# STM32MP23_CM33 register map
File version: 1.2
CPU: CM33 r0p1, little endian, MPU, FPU, vendor SysTick, 8 interrupt priority bits
Registers are 32-bit, read-write, reset 0x0 unless marked. A register's access mark holds for its fields unless they carry their own. Offsets are from the block's base; [hi:lo] are bit positions; {n}, {i} and the like mark numbered series; 'fields as' and 'values as' point back to an identical list.

## EXTI1 (part 2 of 2) — EXTI1 address block description
Base 0x44220000
Same registers: EXTI1_S 0x54220000
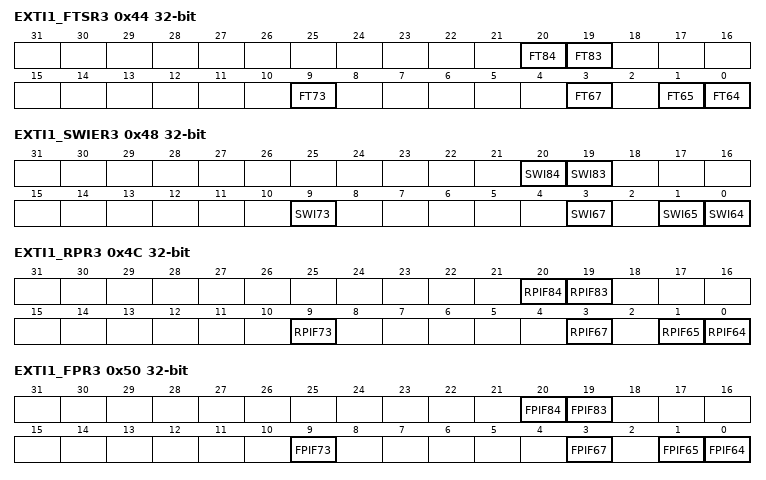
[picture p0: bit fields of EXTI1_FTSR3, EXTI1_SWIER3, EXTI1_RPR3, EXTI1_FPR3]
0x44 EXTI1_FTSR3 — EXTI1 falling trigger selection register
  [20] FT84 — Falling trigger event configuration bit of configurable event input x When SECx is disabled in EXTI1_SECCFGR3, FTx can be accessed with non-secure and secure access. When SECx is enabled in EXTI1_SECCFGR3, FTx can only be accessed with secure access. Non-secure write to FTx is discarded. Non-secure read returns 0. When PRIVx is disabled in EXTI1_PRIVCFGR3, FTx can be accessed with unprivileged and privileged access. When PRIVx is enabled in EXTI1_PRIVCFGR3, FTx can only be accessed with privileged access. Unprivileged write to FTx is discarded. Unprivileged read returns 0. When CID filtering is disabled in EXTI1_ExCIDCFGR, FTx can be accessed by any processor CID. When CID filtering is enabled in EXTI1_ExCIDCFGR, FTx can only be accessed by the allowed processor CID. Dis allowed CID write to FTx is discarded and read returns 0. Note: The configurable event input is edge triggered. No glitch must be generated on this input. If a falling edge on the configurable event input occurs while writing to the register, the associated pending bit is not set. Note: Rising and falling edge triggers can be set for the same configurable event input. In this case, both edges generate a trigger.
    0=Falling trigger disabled (for event and interrupt) for input line; 1=Falling trigger enabled (for event and interrupt) for input line
  [19] FT83 — Falling trigger event configuration bit of configurable event input x When SECx is disabled in EXTI1_SECCFGR3, FTx can be accessed with non-secure and secure access. When SECx is enabled in EXTI1_SECCFGR3, FTx can only be accessed with secure access. Non-secure write to FTx is discarded. Non-secure read returns 0. When PRIVx is disabled in EXTI1_PRIVCFGR3, FTx can be accessed with unprivileged and privileged access. When PRIVx is enabled in EXTI1_PRIVCFGR3, FTx can only be accessed with privileged access. Unprivileged write to FTx is discarded. Unprivileged read returns 0. When CID filtering is disabled in EXTI1_ExCIDCFGR, FTx can be accessed by any processor CID. When CID filtering is enabled in EXTI1_ExCIDCFGR, FTx can only be accessed by the allowed processor CID. Dis allowed CID write to FTx is discarded and read returns 0. Note: The configurable event input is edge triggered. No glitch must be generated on this input. If a falling edge on the configurable event input occurs while writing to the register, the associated pending bit is not set. Note: Rising and falling edge triggers can be set for the same configurable event input. In this case, both edges generate a trigger.
    values as FT84
  [9] FT73 — Falling trigger event configuration bit of configurable event input 73
  [3] FT67 — Falling trigger event configuration bit of configurable event input 67
  [1] FT65 — Falling trigger event configuration bit of configurable event input x
  [0] FT64 — Falling trigger event configuration bit of configurable event input x
0x48 EXTI1_SWIER3 — EXTI1 software interrupt event register
  [20] SWI84 — Software interrupt on event x When SECx is disabled in EXTI1_SECCFGR3, SWIx can be accessed with non-secure and secure access. When SECx is enabled in EXTI1_SECCFGR3, SWIx can only be accessed with secure access. Non-secure write to SWIx is discarded. Non-secure read returns 0. When PRIVx is disabled in EXTI1_PRIVCFGR3, SWIx can be accessed with unprivileged and privileged access. When PRIVx is enabled in EXTI1_PRIVCFGR3, SWIx can only be accessed with privileged access. Unprivileged write to SWIx is discarded. Unprivileged read returns 0. When CID filtering is disabled in EXTI1_ExCIDCFGR, SWIx can be accessed by any processor CID. When CID filtering is enabled in EXTI1_ExCIDCFGR, SWIx can only be accessed by the allowed processor CID. Dis allowed CID write to SWIx is discarded and read returns 0. A software interrupt is generated whatever the setting in EXTI1_RTSR and EXTI1_FTSR. It always returns 0 when read.
    0=Writing 0 has no effect; 1=Writing 1 to this bit triggers a rising edge event on event x (bit auto cleared by hardware)
  [19] SWI83 — Software interrupt on event x When SECx is disabled in EXTI1_SECCFGR3, SWIx can be accessed with non-secure and secure access. When SECx is enabled in EXTI1_SECCFGR3, SWIx can only be accessed with secure access. Non-secure write to SWIx is discarded. Non-secure read returns 0. When PRIVx is disabled in EXTI1_PRIVCFGR3, SWIx can be accessed with unprivileged and privileged access. When PRIVx is enabled in EXTI1_PRIVCFGR3, SWIx can only be accessed with privileged access. Unprivileged write to SWIx is discarded. Unprivileged read returns 0. When CID filtering is disabled in EXTI1_ExCIDCFGR, SWIx can be accessed by any processor CID. When CID filtering is enabled in EXTI1_ExCIDCFGR, SWIx can only be accessed by the allowed processor CID. Dis allowed CID write to SWIx is discarded and read returns 0. A software interrupt is generated whatever the setting in EXTI1_RTSR and EXTI1_FTSR. It always returns 0 when read.
    values as SWI84
  [9] SWI73 — Software interrupt on event 73
  [3] SWI67 — Software interrupt on event 67.
  [1] SWI65 — Software interrupt on event x
  [0] SWI64 — Software interrupt on event x
0x4C EXTI1_RPR3 — EXTI1 rising edge pending register
  [20] RPIF84 — configurable event input x rising edge pending bit This bit is set when the selected rising edge event or an EXTI1_SWIER Software trigger arrives on the configurable event line. This bit is cleared by writing a 1 into the bit. When SECx is disabled in EXTI1_SECCFGR3, RPIFx can be accessed with non-secure and secure access. When SECx is enabled in EXTI1_SECCFGR3, RPIFx can only be accessed with secure access. Non-secure write to this RPIFx is discarded. Non-secure read returns 0. When PRIVx is disabled in EXTI1_PRIVCFGR3, RPIFx can be accessed with unprivileged and privileged access. When PRIVx is enabled in EXTI1_PRIVCFGR3, RPIFx can only be accessed with privileged access. Unprivileged write to RPIFx is discarded. Unprivileged read returns 0. When CID filtering is disabled in EXTI1_ExCIDCFGR, RPIFx can be accessed by any processor CID. When CID filtering is enabled in EXTI1_ExCIDCFGR, RPIFx can only be accessed by the allowed processor CID. Dis allowed CID write to RPIFx is discarded and read returns 0.
    0=No rising edge trigger request occurred; 1=Rising edge trigger request occurred
  [19] RPIF83 — configurable event input x rising edge pending bit This bit is set when the selected rising edge event or an EXTI1_SWIER Software trigger arrives on the configurable event line. This bit is cleared by writing a 1 into the bit. When SECx is disabled in EXTI1_SECCFGR3, RPIFx can be accessed with non-secure and secure access. When SECx is enabled in EXTI1_SECCFGR3, RPIFx can only be accessed with secure access. Non-secure write to this RPIFx is discarded. Non-secure read returns 0. When PRIVx is disabled in EXTI1_PRIVCFGR3, RPIFx can be accessed with unprivileged and privileged access. When PRIVx is enabled in EXTI1_PRIVCFGR3, RPIFx can only be accessed with privileged access. Unprivileged write to RPIFx is discarded. Unprivileged read returns 0. When CID filtering is disabled in EXTI1_ExCIDCFGR, RPIFx can be accessed by any processor CID. When CID filtering is enabled in EXTI1_ExCIDCFGR, RPIFx can only be accessed by the allowed processor CID. Dis allowed CID write to RPIFx is discarded and read returns 0.
    values as RPIF84
  [9] RPIF73 — configurable event input 73 rising edge pending bit
  [3] RPIF67 — configurable event input 67 rising edge pending bit
  [1] RPIF65 — configurable event input x rising edge pending bit
  [0] RPIF64 — configurable event input x rising edge pending bit
0x50 EXTI1_FPR3 — EXTI1 falling edge pending register
  [20] FPIF84 — configurable event input x falling edge pending bit This bit is set when the falling edge event arrives on the configurable event line. This bit is cleared by writing a 1 into the bit. When SECx is disabled in EXTI1_SECCFGR3, FPIFx can be accessed with non-secure and secure access. When SECx is enabled in EXTI1_SECCFGR3, FPIFx can only be accessed with secure access. Non-secure write to FPIFx is discarded. Non-secure read returns 0. When PRIVx is disabled in EXTI1_PRIVCFGR3, FPIFx can be accessed with unprivileged and privileged access. When PRIVx is enabled in EXTI1_PRIVCFGR3, FPIFx can only be accessed with privileged access. Unprivileged write to FPIFx is discarded. Unprivileged read returns 0. When CID filtering is disabled in EXTI1_ExCIDCFGR, FPIFx can be accessed by any processor CID. When CID filtering is enabled in EXTI1_ExCIDCFGR, FPIFx can only be accessed by the allowed processor CID. Dis allowed CID write to FPIFx is discarded and read returns 0.
    0=No falling edge trigger request occurred; 1=Falling edge trigger request occurred
  [19] FPIF83 — configurable event input x falling edge pending bit This bit is set when the falling edge event arrives on the configurable event line. This bit is cleared by writing a 1 into the bit. When SECx is disabled in EXTI1_SECCFGR3, FPIFx can be accessed with non-secure and secure access. When SECx is enabled in EXTI1_SECCFGR3, FPIFx can only be accessed with secure access. Non-secure write to FPIFx is discarded. Non-secure read returns 0. When PRIVx is disabled in EXTI1_PRIVCFGR3, FPIFx can be accessed with unprivileged and privileged access. When PRIVx is enabled in EXTI1_PRIVCFGR3, FPIFx can only be accessed with privileged access. Unprivileged write to FPIFx is discarded. Unprivileged read returns 0. When CID filtering is disabled in EXTI1_ExCIDCFGR, FPIFx can be accessed by any processor CID. When CID filtering is enabled in EXTI1_ExCIDCFGR, FPIFx can only be accessed by the allowed processor CID. Dis allowed CID write to FPIFx is discarded and read returns 0.
    values as FPIF84
  [9] FPIF73 — configurable event input 73 falling edge pending bit
  [3] FPIF67 — configurable 67 falling edge pending bit
  [1] FPIF65 — configurable event input x falling edge pending bit
  [0] FPIF64 — configurable event input x falling edge pending bit
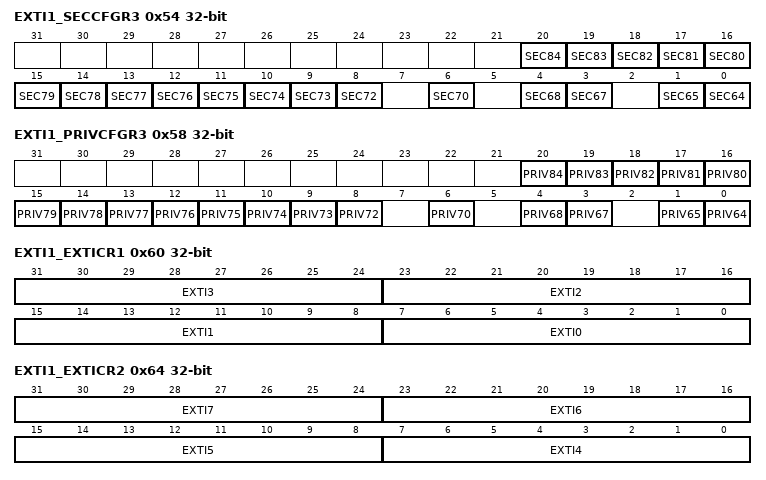
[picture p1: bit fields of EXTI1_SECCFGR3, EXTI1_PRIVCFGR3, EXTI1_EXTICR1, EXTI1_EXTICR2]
0x54 EXTI1_SECCFGR3 — EXTI1 security enable register
  [n-64] SEC{n} (n=72..84) — Security enable on event input x When CID filtering is disabled in EXTI1_ExCIDCFGR, SECx can be accessed by any processor CID. When CID filtering is enabled in EXTI1_ExCIDCFGR, SECx can only be accessed by the allowed processor CID. Dis allowed CID write to SECx is discarded and read returns 0.
    0=Event security disabled (non-secure); 1=Event security enabled (secure)
  [6] SEC70 — Security enable on event input 70
  [4] SEC68 — Security enable on event input x
  [3] SEC67 — Security enable on event input x
  [1] SEC65 — Security enable on event input x
  [0] SEC64 — Security enable on event input x
0x58 EXTI1_PRIVCFGR3 — EXTI1 privilege enable register
  [n-64] PRIV{n} (n=72..84) — Privilege enable on event input x When SECx is disabled in EXTI1_SECCFGR3, PRIVx can be accessed with secure and non-secure access. When SECx is enabled in EXTI1_SECCFGR3, PRIVx can only be written with secure access. Non-secure write to PRIVx is discarded. When CID filtering is disabled in EXTI1_ExCIDCFGR, PRIVx can be accessed by any processor CID. When CID filtering is enabled in EXTI1_ExCIDCFGR, PRIVx can only be accessed by the allowed processor CID. Dis allowed CID write to PRIVx is discarded and read returns 0.
    0=Event privilege disabled (unprivileged; 1=Event privilege enabled (privileged)
  [6] PRIV70 — Privilege enable on event input 70
  [4] PRIV68 — Privilege enable on event input x
  [3] PRIV67 — Privilege enable on event input x
  [1] PRIV65 — Privilege enable on event input x
  [0] PRIV64 — Privilege enable on event input x
0x60 EXTI1_EXTICR1 — EXTI1 external interrupt selection register 1
  [31:24] EXTI3 — EXTI3 GPIO port selection These bits are written by software to select the source input for EXTI3 external interrupt. Others: reserved When SEC3 is disabled in EXTI1_SECCFGR1, this field can be accessed with non-secure and secure access. When SEC3 is enabled in EXTI1_SECCFGR1, this field can only be accessed with secure access. Non-secure write is discarded. Non-secure read returns 0. When PRIV3 is disabled in EXTI1_PRIVCFGR1, this field can be accessed with privileged and unprivileged access. When PRIV3 is enabled in EXTI1_PRIVCFGR1, this field can only be accessed with privileged access. Unprivileged write to this field is discarded, and read returns 0. When CID filtering in EXTI1_E3CIDCFGR is disabled, this field can be accessed by any processor CID. When CID filtering in EXTI1_E3CIDCFGR is enabled, this field can only be accessed by the allowed processor CID. Dis allowed CID write to this field is discarded, and read returns 0.
    0=PA3 pin; 1=PB3 pin; 2=PC3 pin; 3=PD3 pin; 4=PE3 pin; 5=PF3 pin; 6=PG3 pin; 7=PH3 pin; 8=PI3 pin; 9=PJ3 pin; 10=PK3 pin; 11=PZ3 pin
  [23:16] EXTI2 — EXTI2 GPIO port selection These bits are written by software to select the source input for EXTI2 external interrupt. Others: reserved When SEC2 is disabled in EXTI1_SECCFGR1, this field can be accessed with non-secure and secure access. When SEC2 is enabled in EXTI1_SECCFGR1, this field can only be accessed with secure access. Non-secure write is discarded, non-secure read returns 0. When PRIV2 is disabled in EXTI1_PRIVCFGR1, this field can be accessed with privileged and unprivileged access. When PRIV2 is enabled in EXTI1_PRIVCFGR1, this field can only be accessed with privileged access. Unprivileged write to this field is discarded and read returns 0. When CID filtering in EXTI1_E2CIDCFGR is disabled, this field can be accessed by any processor CID. When CID filtering in EXTI1_E2CIDCFGR is enabled, this field can only be accessed by the allowed processor CID. Dis allowed CID write to this field is discarded and read returns 0.
    0=PA2 pin; 1=PB2 pin; 2=PC2 pin; 3=PD2 pin; 4=PE2 pin; 5=PF2 pin; 6=PG2 pin; 7=PH2 pin; 8=PI2 pin; 9=PJ2 pin; 10=PK2 pin; 11=PZ2 pin
  [15:8] EXTI1 — EXTI1 GPIO port selection These bits are written by software to select the source input for EXTI1 external interrupt. Others: reserved When SEC1 is disabled in EXTI1_SECCFGR1, this field can be accessed with non-secure and secure access. When SEC1 is enabled in EXTI1_SECCFGR1, this field can only be accessed with secure access. Non-secure write is discarded, non-secure read returns 0. When PRIV1 is disabled in EXTI1_PRIVCFGR1, this field can be accessed with privileged and unprivileged access. When PRIV1 is enabled in EXTI1_PRIVCFGR1, this field can only be accessed with privileged access. Unprivileged write to this field is discarded and read returns 0. When CID filtering in EXTI1_E1CIDCFGR is disabled, this field can be accessed by any processor CID. When CID filtering in EXTI1_E1CIDCFGR is enabled, this field can only be accessed by the allowed processor CID. Dis allowed CID write to this field is discarded and read returns 0.
    0=PA1 pin; 1=PB1 pin; 2=PC1 pin; 3=PD1 pin; 4=PE1 pin; 5=PF1 pin; 6=PG1 pin; 7=PH1 pin; 8=PI1 pin; 9=PJ1 pin; 10=PK1 pin; 11=PZ1 pin
  [7:0] EXTI0 — EXTI0 GPIO port selection. These bits are written by software to select the source input for EXTI0 external interrupt. Others: reserved When SEC0 is disabled in EXTI1_SECCFGR1 this field can be accessed with non-secure and secure access. When SEC0 is enabled in EXTI1_SECCFGR1, this field can only be accessed with secure access. Non-secure write is discarded, non-secure read returns 0. When PRIV0 is disabled in EXTI1_PRIVCFGR1, this field can be accessed with privileged and unprivileged access. When PRIV0 is enabled in EXTI1_PRIVCFGR1, this field can only be accessed with privileged access. Unprivileged write to this field is discarded and read returns 0. When CID filtering in EXTI1_E0CIDCFGR is disabled, this field can be accessed by any processor CID. When CID filtering in EXTI1_E0CIDCFGR is enabled, this field can only be accessed by the allowed processor CID. Dis allowed CID write to this field is discarded and read returns 0.
    0=PA0 pin; 1=PB0 pin; 2=PC0 pin; 3=PD0 pin; 4=PE0 pin; 5=PF0 pin; 6=PG0 pin; 7=PH0 pin; 8=PI0 pin; 9=PJ0 pin; 10=PK0 pin; 11=PZ0 pin
0x64 EXTI1_EXTICR2 — EXTI1 external interrupt selection register 2
  [8n-25:8n-32] EXTI{n} (n=4..7) — EXTI{n} GPIO port selection. These bits are written by software to select the source input for EXTI{n} external interrupt. Others: reserved When SEC{n} is disabled in EXTI1_SECCFGR1 this field can be accessed with non-secure and secure access. When SEC{n} is enabled in EXTI1_SECCFGR1, this field can only be accessed with secure access. Non-secure write is discarded, non-secure read returns 0. When PRIV{n} is disabled in EXTI1_PRIVCFGR1, this field can be accessed with privileged and unprivileged access. When PRIV{n} is enabled in EXTI1_PRIVCFGR1, this field can only be accessed with privileged access. Unprivileged write to this field is discarded and read returns 0. When CID filtering in EXTI1_E{n}CIDCFGR is disabled, this field can be accessed by any processor CID. When CID filtering in EXTI1_E{n}CIDCFGR is enabled, this field can only be accessed by the allowed processor CID. Dis allowed CID write to this field is discarded and read returns 0.
    0=PA{n} pin; 1=PB{n} pin; 2=PC{n} pin; 3=PD{n} pin; 4=PE{n} pin; 5=PF{n} pin; 6=PG{n} pin; 7=PH{n} pin; 8=PI{n} pin; 9=PJ{n} pin; 10=PK{n} pin; 11=PZ{n} pin
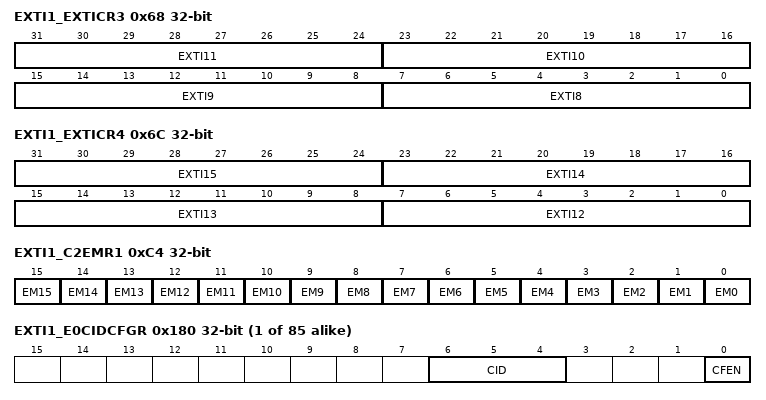
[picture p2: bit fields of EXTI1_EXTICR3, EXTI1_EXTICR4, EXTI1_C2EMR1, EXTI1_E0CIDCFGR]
0x68 EXTI1_EXTICR3 — EXTI1 external interrupt selection register 3
  [31:24] EXTI11 — EXTI11 GPIO port selection. These bits are written by software to select the source input for EXTI11 external interrupt. Others: reserved When SEC11 is disabled in EXTI1_SECCFGR1 this field can be accessed with non-secure and secure access. When SEC11 is enabled in EXTI1_SECCFGR1, this field can only be accessed with secure access. Non-secure write is discarded, non-secure read returns 0. When PRIV11 is disabled in EXTI1_PRIVCFGR1, this field can be accessed with privileged and unprivileged access. When PRIV11 is enabled in EXTI1_PRIVCFGR1, this field can only be accessed with privileged access. Unprivileged write to this field is discarded and read returns 0. When CID filtering in EXTI1_E11CIDCFGR is disabled, this field can be accessed by any processor CID. When CID filtering in EXTI1_E11CIDCFGR is enabled, this field can only be accessed by the allowed processor CID. Dis allowed CID write to this field is discarded and read returns 0.
    0=PA11 pin; 1=PB11 pin; 2=PC11 pin; 3=PD11 pin; 4=PE11 pin; 5=PF11 pin; 6=PG11 pin; 7=PH11 pin; 8=PI11 pin; 9=PJ11 pin; 10=PK11 pin; 11=PZ11 pin
  [23:16] EXTI10 — EXTI10 GPIO port selection. These bits are written by software to select the source input for EXTI10 external interrupt. Others: reserved When SEC10 is disabled in EXTI1_SECCFGR1 this field can be accessed with non-secure and secure access. When SEC120 is enabled in EXTI1_SECCFGR1, this field can only be accessed with secure access. Non-secure write is discarded, non-secure read returns 0. When PRIV120 is disabled in EXTI1_PRIVCFGR1, this field can be accessed with privileged and unprivileged access. When PRIV10 is enabled in EXTI1_PRIVCFGR1, this field can only be accessed with privileged access. Unprivileged write to this field is discarded and read returns 0. When CID filtering in EXTI1_E10CIDCFGR is disabled, this field can be accessed by any processor CID. When CID filtering in EXTI1_E10CIDCFGR is enabled, this field can only be accessed by the allowed processor CID. Dis allowed CID write to this field is discarded and read returns 0.
    0=PA10 pin; 1=PB10 pin; 2=PC10 pin; 3=PD10 pin; 4=PE10 pin; 5=PF10 pin; 6=PG10 pin; 7=PH10 pin; 8=PI10 pin; 9=PJ10 pin; 10=PK10 pin; 11=PZ10 pin
  [15:8] EXTI9 — EXTI9 GPIO port selection. These bits are written by software to select the source input for EXTI9 external interrupt. Others: reserved When SEC9 is disabled in EXTI1_SECCFGR1 this field can be accessed with non-secure and secure access. When SEC9 is enabled in EXTI1_SECCFGR1, this field can only be accessed with secure access. Non-secure write is discarded, non-secure read returns 0. When PRIV9 is disabled in EXTI1_PRIVCFGR1, this field can be accessed with privileged and unprivileged access. When PRIV9 is enabled in EXTI1_PRIVCFGR1, this field can only be accessed with privileged access. Unprivileged write to this field is discarded and read returns 0. When CID filtering in EXTI1_E9CIDCFGR is disabled, this field can be accessed by any processor CID. When CID filtering in EXTI1_E9CIDCFGR is enabled, this field can only be accessed by the allowed processor CID. Dis allowed CID write to this field is discarded and read returns 0.
    0=PA9 pin; 1=PB9 pin; 2=PC9 pin; 3=PD9 pin; 4=PE9 pin; 5=PF9 pin; 6=PG9 pin; 7=PH9 pin; 8=PI9 pin; 9=PJ9 pin; 10=PK9 pin; 11=PZ9 pin
  [7:0] EXTI8 — EXTI8 GPIO port selection. These bits are written by software to select the source input for EXTI8 external interrupt. Others: reserved When SEC8 is disabled in EXTI1_SECCFGR1 this field can be accessed with non-secure and secure access. When SEC8 is enabled in EXTI1_SECCFGR1, this field can only be accessed with secure access. Non-secure write is discarded, non-secure read returns 0. When PRIV8 is disabled in EXTI1_PRIVCFGR1, this field can be accessed with privileged and unprivileged access. When PRIV8 is enabled in EXTI1_PRIVCFGR1, this field can only be accessed with privileged access. Unprivileged write to this field is discarded and read returns 0. When CID filtering in EXTI1_E8CIDCFGR is disabled, this field can be accessed by any processor CID. When CID filtering in EXTI1_E8CIDCFGR is enabled, this field can only be accessed by the allowed processor CID. Dis allowed CID write to this field is discarded and read returns 0.
    0=PA8 pin; 1=PB8 pin; 2=PC8 pin; 3=PD8 pin; 4=PE8 pin; 5=PF8 pin; 6=PG8 pin; 7=PH8 pin; 8=PI8 pin; 9=PJ8 pin; 10=PK8 pin; 11=PZ8 pin
0x6C EXTI1_EXTICR4 — EXTI1 external interrupt selection register 4
  [8n-89:8n-96] EXTI{n} (n=12..15) — EXTI{n} GPIO port selection. These bits are written by software to select the source input for EXTI{n} external interrupt. Others: reserved When SEC{n} is disabled in EXTI1_SECCFGR1 this field can be accessed with non-secure and secure access. When SEC{n} is enabled in EXTI1_SECCFGR1, this field can only be accessed with secure access. Non-secure write is discarded, non-secure read returns 0. When PRIV{n} is disabled in EXTI1_PRIVCFGR1, this field can be accessed with privileged and unprivileged access. When PRIV{n} is enabled in EXTI1_PRIVCFGR1, this field can only be accessed with privileged access. Unprivileged write to this field is discarded and read returns 0. When CID filtering in EXTI1_E{n}CIDCFGR is disabled, this field can be accessed by any processor CID. When CID filtering in EXTI1_E{n}CIDCFGR is enabled, this field can only be accessed by the allowed processor CID. Dis allowed CID write to this field is discarded and read returns 0.
    values as EXTI1_EXTICR2.EXTI4
0x70 EXTI1_LOCKR — EXTI1 lock register
  [0] GLOCK — Global security privilege and CID configuration registers EXTI1_SECCFGRx, EXTI1_PRIVCFGRx,EXTI1_EnCIDCFGR and EXTI1_CmCIDCFGR lock. This bit is written once after reset.
    0=Security, privilege, and CID configuration open can be modified; 1=Security, privilege, and CID configuration locked can no longer be modified
0xC4 EXTI1_C2EMR1 — EXTI1 CPU2 wake-up with event mask register
  [all] fields
    0=Wake-up with event request from line x is masked; 1=Wake-up with event request from line x is unmasked
  [n] EM{n} (n=0..15) — CPU2 wake-up with event on event input x When SECx is disabled in EXTI1_SECCFGR1, EMx can be accessed with non-secure and secure access. When SECx is enabled in EXTI1_SECCFGR1, EMx can only be accessed with secure access. Non-secure write to EMx is discarded. Non-secure read returns 0. When PRIVx is disabled in EXTI1_PRIVCFGR1, EMx can be accessed with privileged and unprivileged access. When PRIVx is enabled in EXTI1_PRIVCFGR1, EMx can only be accessed with privileged access. Unprivileged write to EMx is discarded, and read returns 0. When CID filtering is disabled in EXTI1_ExCIDCFGR, EMx can be accessed by any processor CID. When CID filtering is enabled in EXTI1_ExCIDCFGR, EMx can only be accessed by theallowed processor CID. Disallowed CID write to EMx is discarded, and read returns0.
0xE4 EXTI1_C2EMR3 — EXTI1 CPU2 wake-up with event mask register
  [1] EM65 — CPU2 wake-up with event mask on event input 65 When SEC65 is disabled in EXTI1_SECCFGR3, EM65 can be accessed with non-secure and secure access. When SEC65 is enabled in EXTI1_SECCFGR3, EM65 can only be accessed with secure access. Non-secure write to EM65 is discarded. Non-secure read returns 0. When PRIV65 is disabled in EXTI1_PRIVCFGR3, EM65 can be accessed with privileged and unprivileged access. When PRIV65 is enabled in EXTI1_PRIVCFGR3, EM65 can only be accessed with privileged access. Unprivileged write to EM65 is discarded and read returns 0. When CID filtering is disabled in EXTI1_E65CIDCFGR, EM65 can be accessed by any processor CID. When CID filtering is enabled in EXTI1_E65CIDCFGR, EM65 can only be accessed by the allowed processor CID. Disallowed CID write to EM65 is discarded and read returns0.
    0=Wake-up with event request from line 65 is masked; 1=Wake-up with event request from line 65 is unmasked
{0x180+4i} EXTI1_E{i}CIDCFGR (i=0..84) — EXTI1 event CID configuration register
  [6:4] CID — EXTI event n allowed CID value If CID filtering is disabled in CFEN, these bits are ignored, else EXTI event n allowed processor CID number.
  [0] CFEN — EXTI event n CID filtering enable
    0=Disable EXTI event n filtering (EXTI event n can be accessed by any CIDs); 1=Enable EXTI event n filtering (EXTI event n can only be accessed by the processor with CID = CPUm CID)
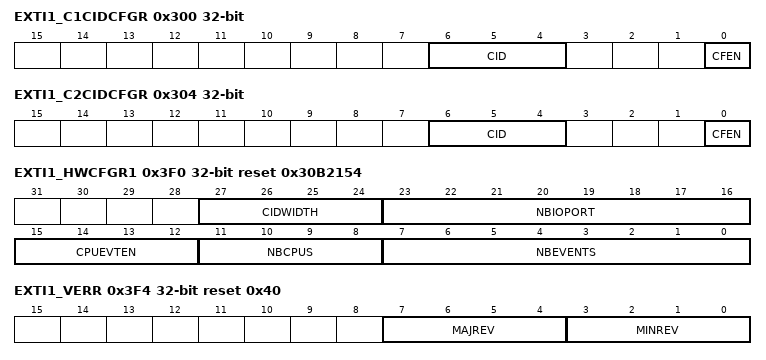
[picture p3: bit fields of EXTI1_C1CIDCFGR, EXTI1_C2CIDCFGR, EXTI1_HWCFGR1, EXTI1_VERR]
0x300 EXTI1_C1CIDCFGR — EXTI1 processor 1 CID configuration register
  [6:4] CID — CPUm CID domain identification If CFEN = 0, these bits are ignored, and there is no CPUm CID filtering, else CPUm CID domain identification number.
  [0] CFEN — CID filtering enabled for CPUm EXTI1_CmIMRx and EXTI1_CmEMRx registers
    0=Disable the CID filtering for CPUm; 1=Enable the CID filtering for CPUm
0x304 EXTI1_C2CIDCFGR — EXTI1 processor 2 CID configuration register
  fields as EXTI1_C1CIDCFGR
0x3C0 EXTI1_HWCFGR13 ro reset 0x1FFF5B — EXTI1 hardware configuration registers 13
  [31:0] SEC — Hardware configuration event security privilege and resource isolation capability
    0=Non-secure, unprivileged, and no resource filtering event; 1=Security, privileged, and resource filtering capable event
0x3C4 EXTI1_HWCFGR12 ro reset 0x7BF7FFF7 — EXTI1 hardware configuration registers 12
  fields as EXTI1_HWCFGR13
0x3C8 EXTI1_HWCFGR11 ro reset 0xFFEFFFFF — EXTI1 hardware configuration registers 11
  fields as EXTI1_HWCFGR13
0x3D8 EXTI1_HWCFGR7 ro reset 0x2 — EXTI1 hardware configuration registers 7
  [31:0] CPUEVENT — Hardware configuration CPU event generation
    0=No CPU event generated; 1=CPU event generated
0x3DC EXTI1_HWCFGR6 ro — EXTI1 hardware configuration registers 6
  fields as EXTI1_HWCFGR7
0x3E0 EXTI1_HWCFGR5 ro reset 0xFFFF — EXTI1 hardware configuration registers 5
  fields as EXTI1_HWCFGR7
0x3E4 EXTI1_HWCFGR4 ro reset 0x18020B — EXTI1 hardware configuration registers 4
  [31:0] EVENT_TRG — Hardware configuration event trigger type
    0=Direct event; 1=Configurable event
0x3E8 EXTI1_HWCFGR3 ro reset 0x3800 — EXTI1 hardware configuration registers 3
  fields as EXTI1_HWCFGR4
0x3EC EXTI1_HWCFGR2 ro reset 0x7FFFF — EXTI1 hardware configuration registers 2
  fields as EXTI1_HWCFGR4
0x3F0 EXTI1_HWCFGR1 ro reset 0x30B2154 — EXTI1 hardware configuration register 1
  [27:24] CIDWIDTH — CID parameters bit width
  [23:16] NBIOPORT — Hardware configuration of number of I/O ports on EXTI (n+1)
  [15:12] CPUEVTEN — Hardware configuration of CPU(m) event output enable.
  [11:8] NBCPUS — Hardware configuration number of CPUs (n+1)
  [7:0] NBEVENTS — Hardware configuration number of event (n+1)
0x3F4 EXTI1_VERR ro reset 0x40 — EXTI1 version register
  [7:4] MAJREV — Major revision number
  [3:0] MINREV — Minor revision number
0x3F8 EXTI1_IPIDR ro reset 0xE0001 — EXTI1 identification register
  [31:0] IPID — EXTI1 identification
0x3FC EXTI1_SIDR ro reset 0xA3C5DD01 — EXTI1 size identification register
  [31:0] SID — Size identification
